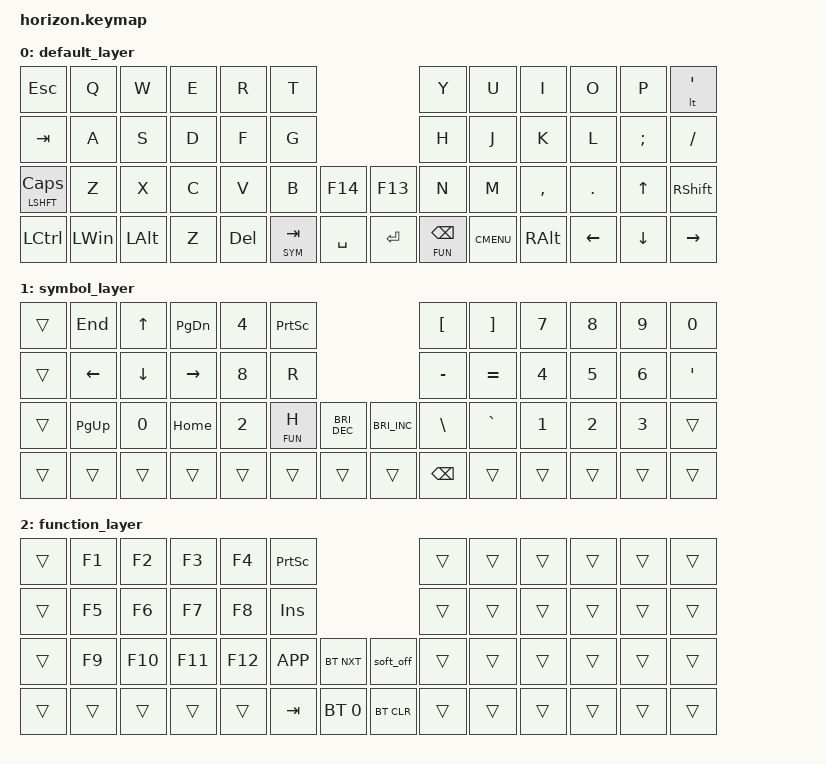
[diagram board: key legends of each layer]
/*
 * Copyright (c) 2021 The ZMK Contributors
 *
 * SPDX-License-Identifier: MIT
 */

#include <behaviors.dtsi>
#include <dt-bindings/zmk/keys.h>
#include <dt-bindings/zmk/bt.h>

#define DEF 0
#define SYM 1
#define FUN 2

&lt {
    tapping-term-ms = <180>;
    flavor = "tap-preferred";
};

/ {
    keymap {
        compatible = "zmk,keymap";

        default_layer {
            bindings = <
                &kp ESC        &kp Q    &kp W    &kp E &kp R   &kp T                           &kp Y        &kp U       &kp I     &kp O    &kp P    &lt SQT
                &kp TAB        &kp A    &kp S    &kp D &kp F   &kp G                           &kp H        &kp J       &kp K     &kp L    &kp SEMI &kp SLASH
                &lt LSHFT CAPS &kp Z    &kp X    &kp C &kp V   &kp B       &kp F14   &kp F13   &kp N        &kp M       &kp COMMA &kp DOT  &kp UP   &kp RSHFT
                &kp LCTRL      &kp LWIN &kp LALT &kp Z &kp DEL &lt SYM TAB &kp SPACE &kp ENTER &lt FUN BSPC &kp K_CMENU &kp RALT  &kp LEFT &kp DOWN &kp RIGHT
            >;
        };

        symbol_layer {
            bindings = <
                &trans &kp END   &kp UP   &kp PG_DN &kp N4 &kp PSCRN                             &kp LBKT  &kp RBKT  &kp N7 &kp N8 &kp N9  &kp N0
                &trans &kp LEFT  &kp DOWN &kp RIGHT &kp N8 &kp R                                 &kp MINUS &kp EQUAL &kp N4 &kp N5 &kp N6  &kp SQT
                &trans &kp PG_UP &kp N0   &kp HOME  &kp N2 &lt FUN H &kp C_BRI_DEC &kp C_BRI_INC &kp BSLH  &kp GRAVE &kp N1 &kp N2 &kp N3  &trans
                &trans &trans    &trans   &trans    &trans &trans    &trans        &trans        &kp BSPC  &trans    &trans &trans &trans  &trans
            >;
        };

        function_layer {
            bindings = <
                &trans &kp F1 &kp F2  &kp F3  &kp F4  &kp PSCRN                          &trans &trans &trans &trans &trans &trans
                &trans &kp F5 &kp F6  &kp F7  &kp F8  &kp INS                            &trans &trans &trans &trans &trans &trans
                &trans &kp F9 &kp F10 &kp F11 &kp F12 &kp K_APP  &bt BT_NXT   &soft_off  &trans &trans &trans &trans &trans &trans
                &trans &trans &trans  &trans  &trans  &kp TAB    &bt BT_SEL 0 &bt BT_CLR &trans &trans &trans &trans &trans &trans
            >;
        };
    };
};
